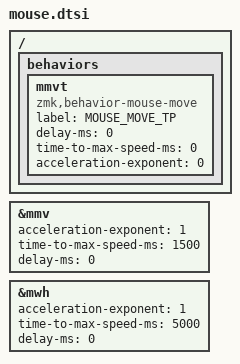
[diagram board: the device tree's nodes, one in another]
#include <dt-bindings/zmk/mouse.h>

&mmv {
  acceleration-exponent = <1>;      // 1
  time-to-max-speed-ms = <1500>;    // 40
  delay-ms = <0>;                   // 0
};

&mwh {
  acceleration-exponent = <1>;      // 0
  time-to-max-speed-ms = <5000>;    // 40
  delay-ms = <0>;                   // 10
};


#define U_MOUSE_MOVE_MAX 1250       // 600
#define U_MOUSE_SCROLL_MAX 100      // 10

#undef MOVE_UP
#undef MOVE_DOWN
#undef MOVE_LEFT
#undef MOVE_RIGHT
#define MOVE_UP MOVE_VERT(-U_MOUSE_MOVE_MAX)
#define MOVE_DOWN MOVE_VERT(U_MOUSE_MOVE_MAX)
#define MOVE_LEFT MOVE_HOR(-U_MOUSE_MOVE_MAX)
#define MOVE_RIGHT MOVE_HOR(U_MOUSE_MOVE_MAX)

#undef SCROLL_UP
#undef SCROLL_DOWN
#undef SCROLL_LEFT
#undef SCROLL_RIGHT
#define SCROLL_UP SCROLL_VERT(U_MOUSE_SCROLL_MAX)
#define SCROLL_DOWN SCROLL_VERT(-U_MOUSE_SCROLL_MAX)
#define SCROLL_LEFT SCROLL_HOR(-U_MOUSE_SCROLL_MAX)
#define SCROLL_RIGHT SCROLL_HOR(U_MOUSE_SCROLL_MAX)

#define U_BTN1 &mkp MB1
#define U_BTN2 &mkp MB2
#define U_BTN3 &mkp MB3
#define U_MS_U &mmv MOVE_UP
#define U_MS_D &mmv MOVE_DOWN
#define U_MS_L &mmv MOVE_LEFT
#define U_MS_R &mmv MOVE_RIGHT
#define U_WH_U &mwh SCROLL_UP
#define U_WH_D &mwh SCROLL_DOWN
#define U_WH_L &mwh SCROLL_LEFT
#define U_WH_R &mwh SCROLL_RIGHT



/ {
	behaviors {
		mmvt: mmvt {
			compatible = "zmk,behavior-mouse-move";
			label = "MOUSE_MOVE_TP";
			#binding-cells = <1>;
			delay-ms = <0>;
			time-to-max-speed-ms = <0>;
			acceleration-exponent = <0>;
		};
	};
};

//teleport cursor
#define M_START_Y &mmvt MOVE_VERT(-30000)// top left
#define M_START_X &mmvt MOVE_HOR(-30000)// top left
#define M_L_DIV 384
#define M_LH_DIV 192
#define M_S_DIV 360
#define M_SH_DIV 180
#define M_SCALE 10

#define DEF_POINTS(NAME, OFFSET_X, OFFSET_Y, DX, DY, MX, MY) \
    ZMK_BEHAVIOR(NAME, macro, \
        wait-ms = <5>; \
        tap-ms = <100>; \
        bindings = <&macro_tap M_START_X>, \
        <&macro_tap M_START_X>, \
        <&macro_tap M_START_X>, \
        <&macro_tap M_START_Y>, \
        <&macro_tap M_START_Y>, \
        <&macro_tap M_START_Y>, \
        <&macro_tap &mmvt MOVE_VERT((OFFSET_Y + MY * DY) * M_SCALE)>,\
        <&macro_tap &mmvt MOVE_VERT((OFFSET_Y + MY * DY) * M_SCALE)>,\
        <&macro_tap &mmvt MOVE_VERT((OFFSET_Y + MY * DY) * M_SCALE)>,\
        <&macro_tap &mmvt MOVE_HOR((OFFSET_X + MX * DX) * M_SCALE)>,\
        <&macro_tap &mmvt MOVE_HOR((OFFSET_X + MX * DX) * M_SCALE)>,\
        <&macro_tap &mmvt MOVE_HOR((OFFSET_X + MX * DX) * M_SCALE)> ;\
    )


//vertical left
DEF_POINTS(LMT1,  M_SH_DIV, M_LH_DIV, M_S_DIV, M_L_DIV, 0, 0)
DEF_POINTS(LMT2,  M_SH_DIV, M_LH_DIV, M_S_DIV, M_L_DIV, 1, 0)
DEF_POINTS(LMT3,  M_SH_DIV, M_LH_DIV, M_S_DIV, M_L_DIV, 2, 0)
DEF_POINTS(LMT4,  M_SH_DIV, M_LH_DIV, M_S_DIV, M_L_DIV, 0, 1)
DEF_POINTS(LMT5,  M_SH_DIV, M_LH_DIV, M_S_DIV, M_L_DIV, 1, 1)
DEF_POINTS(LMT6,  M_SH_DIV, M_LH_DIV, M_S_DIV, M_L_DIV, 2, 1)
DEF_POINTS(LMT7,  M_SH_DIV, M_LH_DIV, M_S_DIV, M_L_DIV, 0, 2)
DEF_POINTS(LMT8,  M_SH_DIV, M_LH_DIV, M_S_DIV, M_L_DIV, 1, 2)
DEF_POINTS(LMT9,  M_SH_DIV, M_LH_DIV, M_S_DIV, M_L_DIV, 2, 2)
DEF_POINTS(LMT10, M_SH_DIV, M_LH_DIV, M_S_DIV, M_L_DIV, 0, 3)
DEF_POINTS(LMT11, M_SH_DIV, M_LH_DIV, M_S_DIV, M_L_DIV, 1, 3)
DEF_POINTS(LMT12, M_SH_DIV, M_LH_DIV, M_S_DIV, M_L_DIV, 2, 3)
DEF_POINTS(LMT13, M_SH_DIV, M_LH_DIV, M_S_DIV, M_L_DIV, 0, 4)
DEF_POINTS(LMT14, M_SH_DIV, M_LH_DIV, M_S_DIV, M_L_DIV, 1, 4)
DEF_POINTS(LMT15, M_SH_DIV, M_LH_DIV, M_S_DIV, M_L_DIV, 2, 4)

//horizontal right
DEF_POINTS(RMT1,  M_LH_DIV + 1080, M_SH_DIV + 429, M_L_DIV, M_S_DIV, 0, 0)
DEF_POINTS(RMT2,  M_LH_DIV + 1080, M_SH_DIV + 429, M_L_DIV, M_S_DIV, 1, 0)
DEF_POINTS(RMT3,  M_LH_DIV + 1080, M_SH_DIV + 429, M_L_DIV, M_S_DIV, 2, 0)
DEF_POINTS(RMT4,  M_LH_DIV + 1080, M_SH_DIV + 429, M_L_DIV, M_S_DIV, 3, 0)
DEF_POINTS(RMT5,  M_LH_DIV + 1080, M_SH_DIV + 429, M_L_DIV, M_S_DIV, 4, 0)
DEF_POINTS(RMT6,  M_LH_DIV + 1080, M_SH_DIV + 429, M_L_DIV, M_S_DIV, 0, 1)
DEF_POINTS(RMT7,  M_LH_DIV + 1080, M_SH_DIV + 429, M_L_DIV, M_S_DIV, 1, 1)
DEF_POINTS(RMT8,  M_LH_DIV + 1080, M_SH_DIV + 429, M_L_DIV, M_S_DIV, 2, 1)
DEF_POINTS(RMT9,  M_LH_DIV + 1080, M_SH_DIV + 429, M_L_DIV, M_S_DIV, 3, 1)
DEF_POINTS(RMT10, M_LH_DIV + 1080, M_SH_DIV + 429, M_L_DIV, M_S_DIV, 4, 1)
DEF_POINTS(RMT11, M_LH_DIV + 1080, M_SH_DIV + 429, M_L_DIV, M_S_DIV, 0, 2)
DEF_POINTS(RMT12, M_LH_DIV + 1080, M_SH_DIV + 429, M_L_DIV, M_S_DIV, 1, 2)
DEF_POINTS(RMT13, M_LH_DIV + 1080, M_SH_DIV + 429, M_L_DIV, M_S_DIV, 2, 2)
DEF_POINTS(RMT14, M_LH_DIV + 1080, M_SH_DIV + 429, M_L_DIV, M_S_DIV, 3, 2)
DEF_POINTS(RMT15, M_LH_DIV + 1080, M_SH_DIV + 429, M_L_DIV, M_S_DIV, 4, 2)



